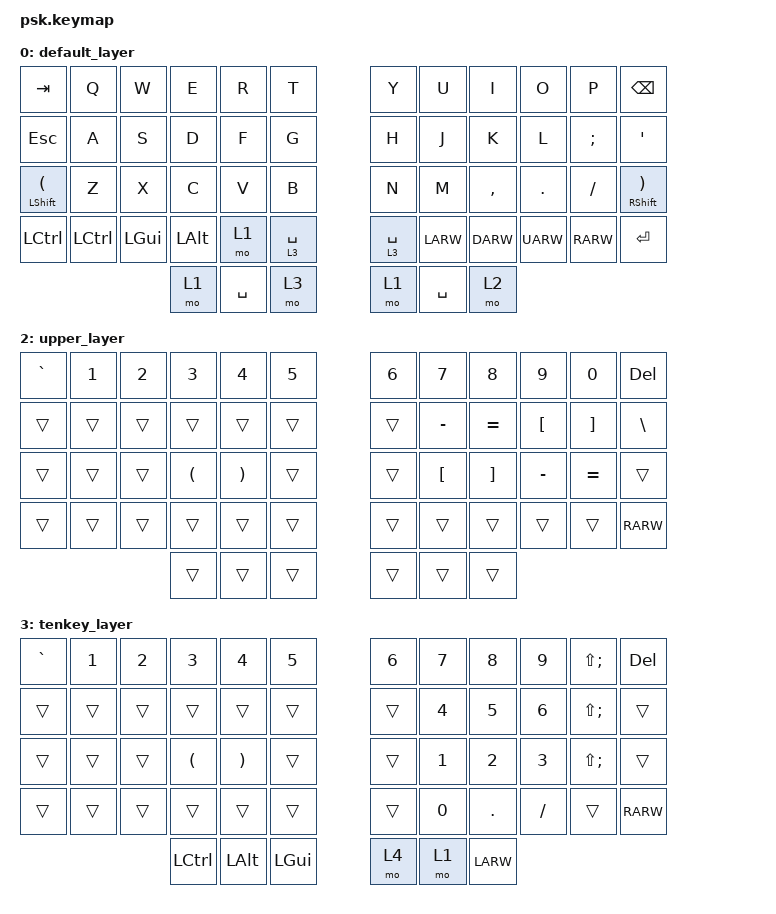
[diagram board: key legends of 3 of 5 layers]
#include <behaviors.dtsi>
#include <dt-bindings/zmk/keys.h>
#include <dt-bindings/zmk/bt.h>

        &mt {
                        tapping-term-ms = <150>;
        };

/ {
        conditional_layers {
                compatible = "zmk,conditional-layers";
                config_layer {
                                                                        if-layers = <1 2>;
                                                                        then-layer = <4>;
                        };
        };
        keymap {
                compatible = "zmk,keymap";

                default_layer {
// ---------------------------------------------------------------------------------
// |  TAB |  Q  |  W  |  E  |  R  |  T  |     |  Y  |  U  |  I  |  O  |  P  |  \   |
// | CAPS |  A  |  S  |  D  |  F  |  G  |     |  H  |  J  |  K  |  L  |  ;  |  ENT |
// | SHFT |  Z  |  X  |  C  |  V  |  B  |     |  N  |  M  |  ,  |  .  |  /  | APOS |
// | CTRL | ALT | GUI | SPC | SPC | SPC |     | SPC | LOW |LARW |DARW |UARW | RARW |
                        bindings = <
   &kp TAB    &kp Q     &kp W     &kp E      &kp R      &kp T                &kp Y      &kp U   &kp I      &kp O     &kp P     &kp BSPC
   &kp ESC   &kp A     &kp S     &kp D      &kp F      &kp G                &kp H      &kp J   &kp K      &kp L     &kp SEMI  &kp SQT
   &mt LSHIFT LPAR &kp Z     &kp X     &kp C      &kp V      &kp B                &kp N      &kp M   &kp COMMA  &kp DOT   &kp FSLH  &mt RSHIFT RPAR
   &kp LCTRL &kp LCTRL  &kp LGUI  &kp LALT  &mo 1 &lt 3 SPACE             &lt 3 SPACE  &kp LARW   &kp DARW   &kp UARW  &kp RARW  &kp RET
                                  &mo 1     &kp SPACE  &mo 3             &mo 1   &kp SPACE   &mo 2
                        >;
                };
                lower_layer {
// |       |  BT1  |  BT2  |  BT3  |  BT4  |  BT5  |          |       |       |       |       |       | BTCLR |
// |       |       |       |       |       |       |          |       |       |       |       |       |       |
// |       |       |       | LPAR  | RPAR  |       |          |       | LBKT  | RBKT  |       |       |       |
// |       |       |       |       |       |       |          |       |       |       |       |       |       |
                        bindings = <
&kp PAUSE_BREAK   &kp F1    &kp F2         &kp F3         &kp F4         &trans         &trans    &trans    &trans   &trans   &trans  &kp DEL
   &trans &kp F5    &kp F6         &kp F7         &kp F8         &kp HOME         &trans &kp UNDER    &kp EQUAL   &kp LBRC   &kp RBRC  &kp BSLH
   &trans &kp F9    &kp F10         &kp F11         &kp F12       &kp END       &trans    &kp LBKT  &kp RBKT &kp MINUS   &kp EQUAL  &trans
   &trans &trans    &trans         &trans         &trans         &trans         &trans                 &trans    &trans    &trans   &trans   &trans  &trans
                                  &trans &trans &trans              &trans  &trans   &trans
                        >;
                };
                upper_layer {
// |       |  BT1  |  BT2  |  BT3  |  BT4  |  BT5  |          |       |       |       |       |       | BTCLR |
// |       |       |       |       |       |       |          |       |       |       |       |       |       |
// |       |       |       | LPAR  | RPAR  |       |          |       | LBKT  | RBKT  |       |       |       |
// |       |       |       |       |       |       |          |       |       |       |       |       |       |
                        bindings = <
   &kp GRAVE    &kp N1         &kp N2         &kp N3         &kp N4         &kp N5                 &kp N6    &kp N7    &kp N8   &kp N9   &kp N0  &kp DEL
   &trans    &trans         &trans         &trans         &trans         &trans                 &trans    &kp MINUS    &kp EQUAL   &kp LBKT   &kp RBKT  &kp BSLH
   &trans    &trans         &trans         &kp LPAR       &kp RPAR       &trans                 &trans    &kp LBKT  &kp RBKT &kp MINUS   &kp EQUAL  &trans
   &trans    &trans         &trans         &trans         &trans         &trans                 &trans    &trans    &trans   &trans   &trans  &kp RARW
                                  &trans &trans &trans              &trans  &trans   &trans
                        >;
                };
                tenkey_layer {
// |       |  BT1  |  BT2  |  BT3  |  BT4  |  BT5  |          |       |       |       |       |       | BTCLR |
// |       |       |       |       |       |       |          |       |       |       |       |       |       |
// |       |       |       | LPAR  | RPAR  |       |          |       | LBKT  | RBKT  |       |       |       |
// |       |       |       |       |       |       |          |       |       |       |       |       |       |
                        bindings = <
   &kp GRAVE    &kp N1         &kp N2         &kp N3         &kp N4         &kp N5                 &kp N6    &kp N7    &kp N8   &kp N9   &kp LS(SEMI)  &kp DEL
   &trans    &trans         &trans         &trans         &trans         &trans                 &trans    &kp N4    &kp N5   &kp N6   &kp LS(SEMI)  &trans
   &trans    &trans         &trans         &kp LPAR       &kp RPAR       &trans                 &trans    &kp N1  &kp N2 &kp N3   &kp LS(SEMI)  &trans
   &trans    &trans         &trans         &trans         &trans         &trans                 &trans    &kp N0    &kp DOT   &kp FSLH   &trans  &kp RARW
                                  &kp LCTRL  &kp LALT  &kp LGUI              &mo 4  &mo 1   &kp LARW
                        >;
                };
                config_layer {
// |       |  BT1  |  BT2  |  BT3  |  BT4  |  BT5  |          |       |       |       |       |       | BTCLR |
// |       |       |       |       |       |       |          |       |       |       |       |       |       |
// |       |       |       | LPAR  | RPAR  |       |          |       | LBKT  | RBKT  |       |       |       |
// |       |       |       |       |       |       |          |       |       |       |       |       |       |
                        bindings = <
   &kp GRAVE    &kp N1         &kp N2         &kp N3         &kp N4         &kp N5                 &kp N6    &kp KP_N7    &kp LS(LC(LA(I)))   &kp LS(LC(LA(O)))   &kp LC(N9)  &kp DEL
   &bt BT_CLR    &bt BT_SEL 0         &bt BT_SEL 1         &bt BT_SEL 2         &bt BT_SEL 3         &bt BT_SEL 4                 &kp LC(LA(H))    &kp LC(LA(J))  &kp LC(LA(K)) &kp LC(LA(L))   &trans  &trans
   &trans    &trans         &trans         &kp LPAR       &kp RPAR       &trans                 &trans    &kp KP_N1  &kp KP_N2 &kp KP_N3   &kp EQUAL  &trans
   &trans    &trans         &trans         &trans         &trans         &trans                 &trans    &kp KP_N0    &kp DOT   &kp FSLH   &trans  &kp RARW
                                  &kp LCTRL  &kp LALT  &kp LGUI              &kp SPACE  &mo 1   &kp LARW
                        >;
                };
        };
};
